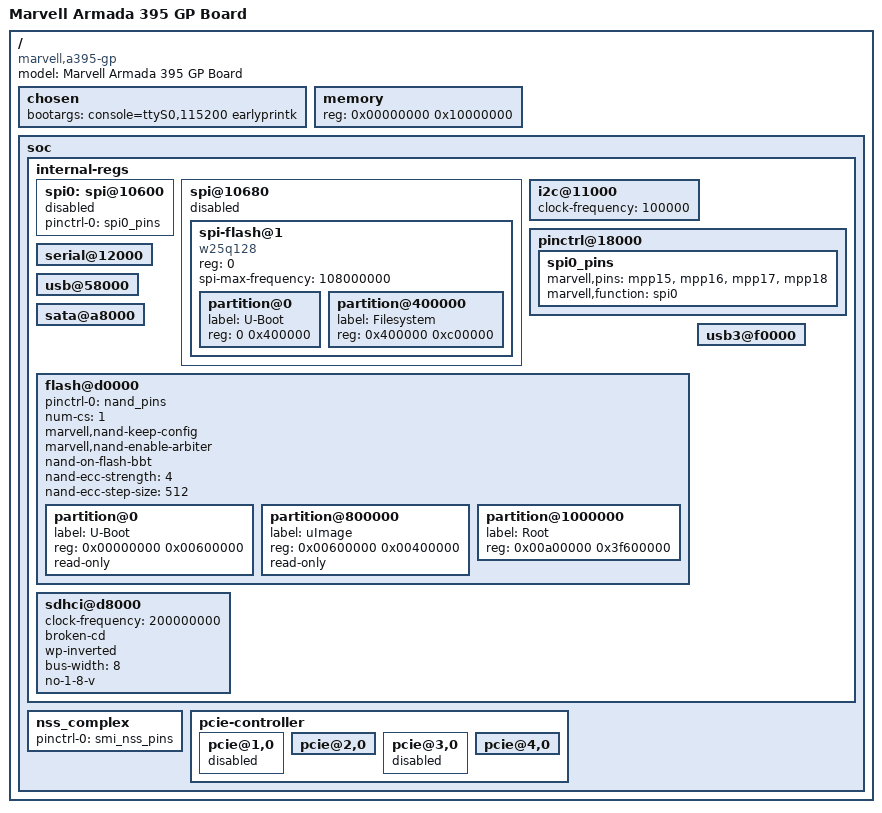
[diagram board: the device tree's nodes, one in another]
/*
 * Device Tree file for Marvell Armada 395 GP board
 * (DB-88F6925-GW-2.5G)
 *
 * Copyright (C) 2014 Marvell
 *
 * Grzegorz Jaszczyk <jaz@semihalf.com>
 *
 * This file is dual-licensed: you can use it either under the terms
 * of the GPL or the X11 license, at your option. Note that this dual
 * licensing only applies to this file, and not this project as a
 * whole.
 *
 *  a) This file is licensed under the terms of the GNU General Public
 *     License version 2.  This program is licensed "as is" without
 *     any warranty of any kind, whether express or implied.
 *
 * Or, alternatively,
 *
 *  b) Permission is hereby granted, free of charge, to any person
 *     obtaining a copy of this software and associated documentation
 *     files (the "Software"), to deal in the Software without
 *     restriction, including without limitation the rights to use,
 *     copy, modify, merge, publish, distribute, sublicense, and/or
 *     sell copies of the Software, and to permit persons to whom the
 *     Software is furnished to do so, subject to the following
 *     conditions:
 *
 *     The above copyright notice and this permission notice shall be
 *     included in all copies or substantial portions of the Software.
 *
 *     THE SOFTWARE IS PROVIDED "AS IS", WITHOUT WARRANTY OF ANY KIND,
 *     EXPRESS OR IMPLIED, INCLUDING BUT NOT LIMITED TO THE WARRANTIES
 *     OF MERCHANTABILITY, FITNESS FOR A PARTICULAR PURPOSE AND
 *     NONINFRINGEMENT. IN NO EVENT SHALL THE AUTHORS OR COPYRIGHT
 *     HOLDERS BE LIABLE FOR ANY CLAIM, DAMAGES OR OTHER LIABILITY,
 *     WHETHER IN AN ACTION OF CONTRACT, TORT OR OTHERWISE, ARISING
 *     FROM, OUT OF OR IN CONNECTION WITH THE SOFTWARE OR THE USE OR
 *     OTHER DEALINGS IN THE SOFTWARE.
 */

/dts-v1/;
#include "armada-395.dtsi"

/ {
	model = "Marvell Armada 395 GP Board";
	compatible = "marvell,a395-gp", "marvell,armada395", "marvell,armada380";

	chosen {
		bootargs = "console=ttyS0,115200 earlyprintk";
	};

	memory {
		device_type = "memory";
		reg = <0x00000000 0x10000000>; /* 256 MB */
	};

	soc {
		ranges = <MBUS_ID(0xf0, 0x01) 0 0xf1000000 0x100000
			  MBUS_ID(0x01, 0x1d) 0 0xfff00000 0x100000>;

		internal-regs {
			spi0: spi@10600 {
				status = "disabled";
				pinctrl-0 = <&spi0_pins>;
				pinctrl-names = "default";
			};

			spi@10680 {
				status = "disabled";

				spi-flash@1 {
					#address-cells = <1>;
					#size-cells = <1>;
					compatible = "w25q128", "jedec,spi-nor";
					reg = <0>; /* Chip select 0 */
					spi-max-frequency = <108000000>;

					partition@0 {
						label = "U-Boot";
						reg = <0 0x400000>;
					};
					partition@400000 {
						label = "Filesystem";
						reg = <0x400000 0xc00000>;
					};
				};
			};

			i2c@11000 {
				status = "okay";
				clock-frequency = <100000>;
			};

			pinctrl@18000 {
				spi0_pins: spi0_pins {
					marvell,pins = "mpp15", "mpp16", "mpp17",
						       "mpp18";
					marvell,function = "spi0";
				};
			};

			serial@12000 {
				status = "okay";
			};

			usb@58000 {
				status = "okay";
			};

			sata@a8000 {
				status = "okay";
			};

			flash@d0000 {
				status = "okay";
				pinctrl-0 = <&nand_pins>;
				pinctrl-names = "default";
				num-cs = <1>;
				marvell,nand-keep-config;
				marvell,nand-enable-arbiter;
				nand-on-flash-bbt;
				nand-ecc-strength = <4>;
				nand-ecc-step-size = <512>;

				partition@0 {
					label = "U-Boot";
					reg = <0x00000000 0x00600000>;
					read-only;
				};

				partition@800000 {
					label = "uImage";
					reg = <0x00600000 0x00400000>;
					read-only;
				};

				partition@1000000 {
					label = "Root";
					reg = <0x00a00000 0x3f600000>;
				};
			};

			sdhci@d8000 {
				clock-frequency = <200000000>;
				broken-cd;
				wp-inverted;
				bus-width = <8>;
				status = "okay";
				no-1-8-v;
			};

			usb3@f0000 {
				status = "okay";
			};
		};

		nss_complex {
			status = "okay";
			pinctrl-0 = <&smi_nss_pins>;
			pinctrl-names="default";
		};

		pcie-controller {
			status = "okay";
			/*
			 * The three PCIe units are accessible through
			 * standard PCIe slots on the board.
			 */
			pcie@1,0 {
				/* Port 0, Lane 0 */
				status = "disabled";
			};
			pcie@2,0 {
				/* Port 1, Lane 0 */
				status = "okay";
			};
			pcie@3,0 {
				/* Port 2, Lane 0 */
				status = "disabled";
			};
			pcie@4,0 {
				/* Port 3, Lane 0 */
				status = "okay";
			};
		};
	};
};
